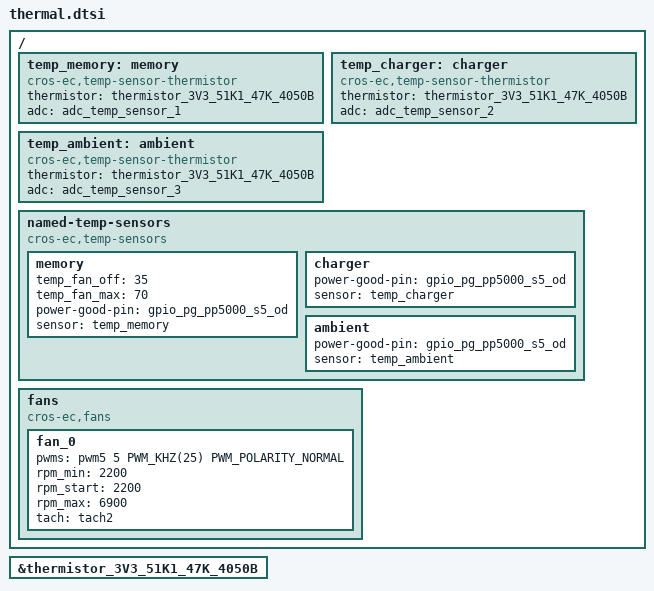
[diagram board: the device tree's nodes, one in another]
/* Copyright 2024 The ChromiumOS Authors
 * Use of this source code is governed by a BSD-style license that can be
 * found in the LICENSE file.
 */
#include <cros/thermistor/thermistor.dtsi>

 / {
	temp_memory: memory {
		compatible = "cros-ec,temp-sensor-thermistor";
		thermistor = <&thermistor_3V3_51K1_47K_4050B>;
		adc = <&adc_temp_sensor_1>;
	};
	temp_charger: charger {
		compatible = "cros-ec,temp-sensor-thermistor";
		thermistor = <&thermistor_3V3_51K1_47K_4050B>;
		adc = <&adc_temp_sensor_2>;
	};
	temp_ambient: ambient {
		compatible = "cros-ec,temp-sensor-thermistor";
		thermistor = <&thermistor_3V3_51K1_47K_4050B>;
		adc = <&adc_temp_sensor_3>;
	};

	named-temp-sensors {
		compatible = "cros-ec,temp-sensors";
		memory {
			temp_fan_off = <35>;
			temp_fan_max = <70>;
			power-good-pin = <&gpio_pg_pp5000_s5_od>;
			sensor = <&temp_memory>;
		};
		charger {
			power-good-pin = <&gpio_pg_pp5000_s5_od>;
			sensor = <&temp_charger>;
		};
		ambient {
			power-good-pin = <&gpio_pg_pp5000_s5_od>;
			sensor = <&temp_ambient>;
		};
	};

	fans {
		compatible = "cros-ec,fans";

		fan_0 {
			pwms = <&pwm5 5 PWM_KHZ(25) PWM_POLARITY_NORMAL>;
			rpm_min = <2200>;
			rpm_start = <2200>;
			rpm_max = <6900>;
			tach = <&tach2>;
		};
	};
 };

&thermistor_3V3_51K1_47K_4050B {
	status = "okay";
};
